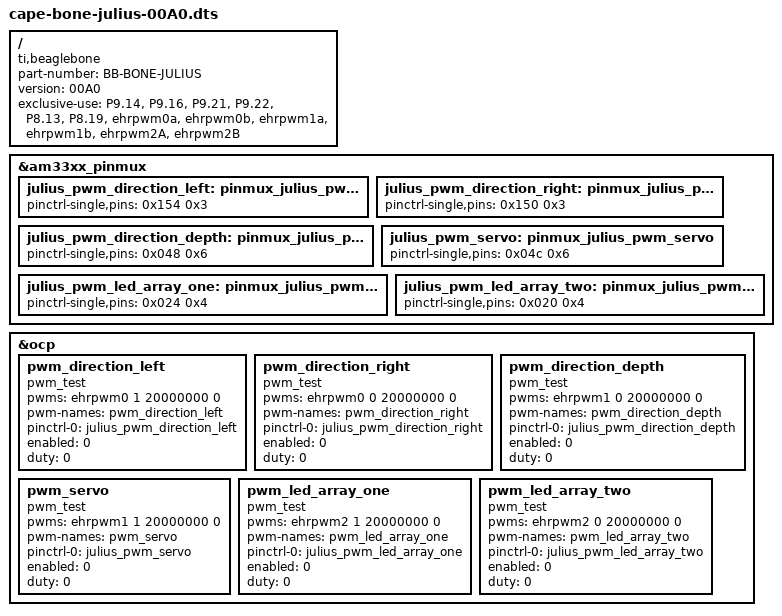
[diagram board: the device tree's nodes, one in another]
/*
 * Copyright (C) 2014 Shrkey, Dark Water Foundation        <barry@shrkey.com>
 *
 * This program is free software; you can redistribute it and/or modify
 * it under the terms of the GNU General Public License version 2 as
 * published by the Free Software Foundation.
 */
/dts-v1/;
/plugin/;

/ {
        compatible = "ti,beaglebone", "ti,beaglebone-black";

        /* identification */
        part-number = "BB-BONE-JULIUS";
        version = "00A0";

        /* state the resources this cape uses */
        exclusive-use =
                /* the pin header P9 uses */
                "P9.14", /* PWM - ehrpwm1b - vertical thruster   	*/
                "P9.16", /* PWM - ehrpwm1a - servo 1                */
                "P9.21", /* PWM - ehrpwm0b - left thruster          */
				"P9.22", /* PWM - ehrpwm0a - right thruster         */
				/* lights */
				"P8.13",		/* pwm: ehrpwm2B */
				"P8.19",		/* pwm: ehrpwm2A */

				/* Hardware IP cores in use */
				"ehrpwm0a",
				"ehrpwm0b",
				"ehrpwm1a",
				"ehrpwm1b",
				"ehrpwm2A",
				"ehrpwm2B";

        fragment@0 {
                target = <&am33xx_pinmux>;
                __overlay__ {
                        julius_pwm_direction_left: pinmux_julius_pwm_direction_left {
                                pinctrl-single,pins = <0x154  0x3>; /* P9_21 (ZCZ ball B17) | MODE 3 */
                        };
                        julius_pwm_direction_right: pinmux_julius_pwm_direction_right {
                                pinctrl-single,pins = <0x150  0x3>; /* P9_22 (ZCZ ball A17) | MODE 3 */
                        };
                        julius_pwm_direction_depth: pinmux_julius_pwm_direction_depth {
                                pinctrl-single,pins = <0x048  0x6>; /* P9_14 (ZCZ ball U14) | MODE 6 */
                        };
                        julius_pwm_servo: pinmux_julius_pwm_servo {
                                pinctrl-single,pins = <0x04c  0x6>; /* P9_16 (ZCZ ball T14) | MODE 6 */
                        };
                        julius_pwm_led_array_one: pinmux_julius_pwm_led_array_one {
								pinctrl-single,pins = <0x024  0x4>; /* P8_13 (ZCZ ball T10) | MODE 4 */
						};
						julius_pwm_led_array_two: pinmux_julius_pwm_led_array_two {
								pinctrl-single,pins = <0x020  0x4>; /* P8_19 (ZCZ ball U10) | MODE 4 */
						};                                        
                };
        };
		
		fragment@1 {
		        target = <&ocp>;
		        __overlay__ {
		            pwm_direction_left {
		                compatible    = "pwm_test";
		                pwms         = <&ehrpwm0 1 20000000 0>;
		                pwm-names     = "pwm_direction_left";
		                pinctrl-names    = "default";
		                pinctrl-0    = <&julius_pwm_direction_left>;
		                enabled        = <0>;
		                duty        = <0>;
		                status         = "okay";
		            };
		            pwm_direction_right {
		                compatible    = "pwm_test";
		                pwms         = <&ehrpwm0 0 20000000 0>;
		                pwm-names     = "pwm_direction_right";
		                pinctrl-names    = "default";
		                pinctrl-0    = <&julius_pwm_direction_right>;
		                enabled        = <0>;
		                duty        = <0>;
		                status         = "okay";
		            };
		            pwm_direction_depth {
		                compatible    = "pwm_test";
		                pwms         = <&ehrpwm1 0 20000000 0>;
		                pwm-names     = "pwm_direction_depth";
		                pinctrl-names    = "default";
		                pinctrl-0    = <&julius_pwm_direction_depth>;
		                enabled        = <0>;
		                duty        = <0>;
		                status         = "okay";
		            };
		            pwm_servo {
		                compatible    = "pwm_test";
		                pwms         = <&ehrpwm1 1 20000000 0>;
		                pwm-names     = "pwm_servo";
		                pinctrl-names    = "default";
		                pinctrl-0    = <&julius_pwm_servo>;
		                enabled        = <0>;
		                duty        = <0>;
		                status         = "okay";
		            };
		            pwm_led_array_one {
						compatible	= "pwm_test";
						pwms 		= <&ehrpwm2 1 20000000 0>;
						pwm-names 	= "pwm_led_array_one";
					    pinctrl-names	= "default";
					    pinctrl-0	= <&julius_pwm_led_array_one>;
						enabled		= <0>;
						duty		= <0>;
						status 		= "okay";
					};
					pwm_led_array_two {
						compatible	= "pwm_test";
						pwms 		= <&ehrpwm2 0 20000000 0>;
						pwm-names 	= "pwm_led_array_two";
					    pinctrl-names	= "default";
					    pinctrl-0	= <&julius_pwm_led_array_two>;
						enabled		= <0>;
						duty		= <0>;
						status 		= "okay";
					};
		        };
		    };


};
